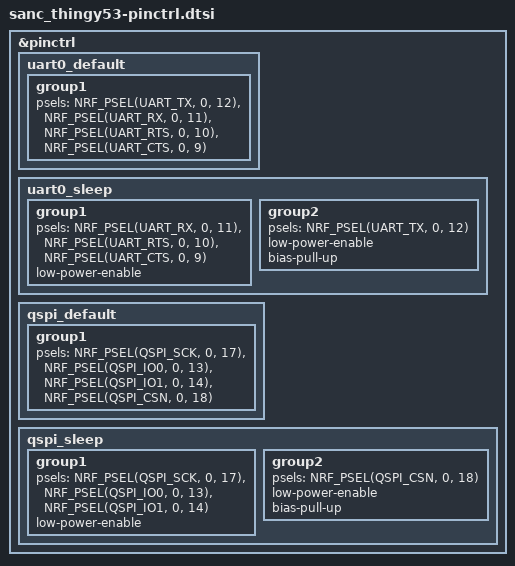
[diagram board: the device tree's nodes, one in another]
&pinctrl {
	uart0_default: uart0_default {
		group1 {
			psels = <NRF_PSEL(UART_TX, 0, 12)>,
				<NRF_PSEL(UART_RX, 0, 11)>,
				<NRF_PSEL(UART_RTS, 0, 10)>,
				<NRF_PSEL(UART_CTS, 0, 9)>;
		};
	};

	uart0_sleep: uart0_sleep {
		group1 {
			psels = <NRF_PSEL(UART_RX, 0, 11)>,
				<NRF_PSEL(UART_RTS, 0, 10)>,
				<NRF_PSEL(UART_CTS, 0, 9)>;
			low-power-enable;
		};

		group2 {
			psels = <NRF_PSEL(UART_TX, 0, 12)>;
			low-power-enable;
			bias-pull-up;
		};
	};

	qspi_default: qspi_default {
		group1 {
			psels = <NRF_PSEL(QSPI_SCK, 0, 17)>,
				<NRF_PSEL(QSPI_IO0, 0, 13)>,
				<NRF_PSEL(QSPI_IO1, 0, 14)>,
				<NRF_PSEL(QSPI_CSN, 0, 18)>;
		};
	};

	qspi_sleep: qspi_sleep {
		group1 {
			psels = <NRF_PSEL(QSPI_SCK, 0, 17)>,
				<NRF_PSEL(QSPI_IO0, 0, 13)>,
				<NRF_PSEL(QSPI_IO1, 0, 14)>;
			low-power-enable;
		};

		group2 {
			psels = <NRF_PSEL(QSPI_CSN, 0, 18)>;
			low-power-enable;
			bias-pull-up;
		};
	};
};

